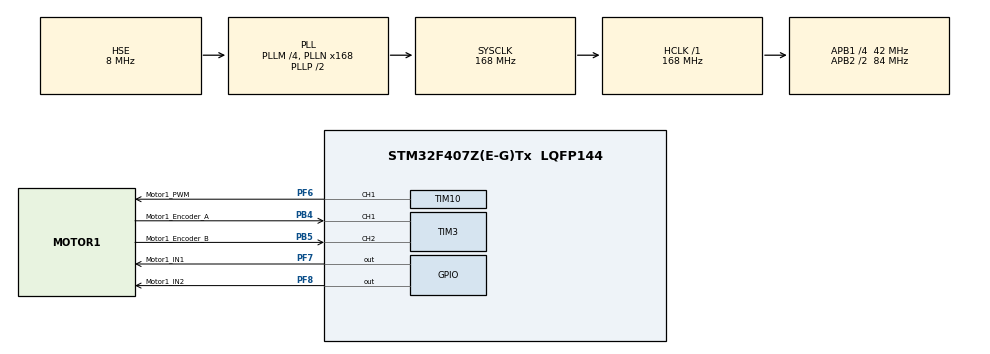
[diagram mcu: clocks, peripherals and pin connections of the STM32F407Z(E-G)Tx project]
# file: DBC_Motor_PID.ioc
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Mcu.Family=STM32F4
Mcu.Name=STM32F407Z(E-G)Tx
Mcu.Package=LQFP144
NVIC.PriorityGroup=NVIC_PRIORITYGROUP_4
NVIC.TIM3_IRQn=true\:0\:0\:false\:false\:true\:true\:true\:true
NVIC.TIM6_DAC_IRQn=true\:0\:0\:false\:false\:true\:true\:true\:true
NVIC.TIM7_IRQn=true\:0\:0\:false\:false\:true\:true\:true\:true
PA13.Mode=Serial_Wire
PA13.Signal=SYS_JTMS-SWDIO
PA14.Mode=Serial_Wire
PA14.Signal=SYS_JTCK-SWCLK
PB4.GPIO_Label=Motor1_Encoder_A
PB4.Signal=S_TIM3_CH1
PB5.GPIO_Label=Motor1_Encoder_B
PB5.Signal=S_TIM3_CH2
PF6.GPIO_Label=Motor1_PWM
PF6.Signal=S_TIM10_CH1
PF7.GPIO_Label=Motor1_IN1
PF7.Signal=GPIO_Output
PF8.GPIO_Label=Motor1_IN2
PF8.Signal=GPIO_Output
PH0-OSC_IN.Mode=HSE-External-Oscillator
PH0-OSC_IN.Signal=RCC_OSC_IN
PH1-OSC_OUT.Mode=HSE-External-Oscillator
PH1-OSC_OUT.Signal=RCC_OSC_OUT
ProjectManager.HeapSize=0x200
ProjectManager.StackSize=0x400
ProjectManager.TargetToolchain=MDK-ARM V5.32
RCC.48MHZClocksFreq_Value=84000000
RCC.AHBFreq_Value=168000000
RCC.APB1CLKDivider=RCC_HCLK_DIV4
RCC.APB1Freq_Value=42000000
RCC.APB1TimFreq_Value=84000000
RCC.APB2CLKDivider=RCC_HCLK_DIV2
RCC.APB2Freq_Value=84000000
RCC.APB2TimFreq_Value=168000000
RCC.CortexFreq_Value=168000000
RCC.HCLKFreq_Value=168000000
RCC.HSE_VALUE=8000000
RCC.HSI_VALUE=16000000
RCC.LSE_VALUE=32768
RCC.PLLM=4
RCC.PLLN=168
RCC.PLLSourceVirtual=RCC_PLLSOURCE_HSE
RCC.SYSCLKFreq_VALUE=168000000
RCC.SYSCLKSource=RCC_SYSCLKSOURCE_PLLCLK
RCC.VCOOutputFreq_Value=336000000
SH.S_TIM10_CH1.0=TIM10_CH1,PWM Generation1 CH1
SH.S_TIM3_CH1.0=TIM3_CH1,Encoder_Interface
SH.S_TIM3_CH2.0=TIM3_CH2,Encoder_Interface
TIM10.Channel=TIM_CHANNEL_1
TIM10.Period=10000-1
TIM10.Prescaler=168-1
TIM3.EncoderMode=TIM_ENCODERMODE_TI12
TIM6.Period=5000-1
TIM6.Prescaler=84-1
TIM7.Period=1000-1
TIM7.Prescaler=84-1
VP_TIM10_VS_ClockSourceINT.Mode=Enable_Timer
VP_TIM6_VS_ClockSourceINT.Mode=Enable_Timer
VP_TIM7_VS_ClockSourceINT.Mode=Enable_Timer
board=custom

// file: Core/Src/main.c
/* USER CODE BEGIN Header */
/**
  ******************************************************************************
  * @file           : main.c
  * @brief          : Main program body
  ******************************************************************************
  * @attention
  *
  * Copyright (c) 2023 STMicroelectronics.
  * All rights reserved.
  *
  * This software is licensed under terms that can be found in the LICENSE file
  * in the root directory of this software component.
  * If no LICENSE file comes with this software, it is provided AS-IS.
  *
  ******************************************************************************
  */
/* USER CODE END Header */
#include "main.h"
#include "tim.h"
#include "gpio.h"

void SystemClock_Config(void);

int main(void)
{

  /* MCU Configuration--------------------------------------------------------*/

  /* Reset of all peripherals, Initializes the Flash interface and the Systick. */
  HAL_Init();

  /* Configure the system clock */
  SystemClock_Config();

  /* Initialize all configured peripherals */
  MX_GPIO_Init();
  MX_TIM3_Init();
  MX_TIM7_Init();
  MX_TIM10_Init();
  MX_TIM6_Init();
  /* USER CODE BEGIN 2 */
	PID_devices_Init();

	HAL_TIM_Encoder_Start_IT(&htim3,TIM_CHANNEL_1);
	HAL_TIM_Encoder_Start_IT(&htim3,TIM_CHANNEL_2);

  HAL_TIM_Base_Start_IT(&htim7);

  HAL_TIM_PWM_Start(&htim10,TIM_CHANNEL_1);
  /* USER CODE END 2 */

  /* Infinite loop */
  while (1)
  {

    /* USER CODE BEGIN 3 */
		fp32 pos;
		pos = 10000;
		Motor_CMD_PID(call,pos,0);
		HAL_Delay(3);

//		fp32 vel;
//		vel = 3000;
//		Motor_CMD_PID(velocity,vel,0);
//		HAL_Delay(10);

//		Motor_Set_Pulse(7000,0);
//		HAL_GPIO_WritePin(Motor1_IN1_GPIO_Port,Motor1_IN1_Pin,GPIO_PIN_SET);
//		HAL_GPIO_WritePin(Motor1_IN2_GPIO_Port,Motor1_IN2_Pin,GPIO_PIN_RESET);

  }
  /* USER CODE END 3 */
}

void SystemClock_Config(void)
{
  RCC_OscInitTypeDef RCC_OscInitStruct = {0};
  RCC_ClkInitTypeDef RCC_ClkInitStruct = {0};

  /** Configure the main internal regulator output voltage
  */
  __HAL_RCC_PWR_CLK_ENABLE();
  __HAL_PWR_VOLTAGESCALING_CONFIG(PWR_REGULATOR_VOLTAGE_SCALE1);

  /** Initializes the RCC Oscillators according to the specified parameters
  * in the RCC_OscInitTypeDef structure.
  */
  RCC_OscInitStruct.OscillatorType = RCC_OSCILLATORTYPE_HSE;
  RCC_OscInitStruct.HSEState = RCC_HSE_ON;
  RCC_OscInitStruct.PLL.PLLState = RCC_PLL_ON;
  RCC_OscInitStruct.PLL.PLLSource = RCC_PLLSOURCE_HSE;
  RCC_OscInitStruct.PLL.PLLM = 4;
  RCC_OscInitStruct.PLL.PLLN = 168;
  RCC_OscInitStruct.PLL.PLLP = RCC_PLLP_DIV2;
  RCC_OscInitStruct.PLL.PLLQ = 4;
  if (HAL_RCC_OscConfig(&RCC_OscInitStruct) != HAL_OK)
  {
    Error_Handler();
  }

  /** Initializes the CPU, AHB and APB buses clocks
  */
  RCC_ClkInitStruct.ClockType = RCC_CLOCKTYPE_HCLK|RCC_CLOCKTYPE_SYSCLK
                              |RCC_CLOCKTYPE_PCLK1|RCC_CLOCKTYPE_PCLK2;
  RCC_ClkInitStruct.SYSCLKSource = RCC_SYSCLKSOURCE_PLLCLK;
  RCC_ClkInitStruct.AHBCLKDivider = RCC_SYSCLK_DIV1;
  RCC_ClkInitStruct.APB1CLKDivider = RCC_HCLK_DIV4;
  RCC_ClkInitStruct.APB2CLKDivider = RCC_HCLK_DIV2;

  if (HAL_RCC_ClockConfig(&RCC_ClkInitStruct, FLASH_LATENCY_5) != HAL_OK)
  {
    Error_Handler();
  }
}

void Error_Handler(void)
{
  __disable_irq();
  while (1)
  {
  }
}
